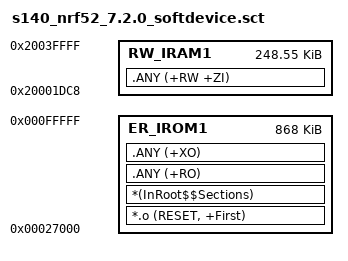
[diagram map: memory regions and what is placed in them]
; *************************************************************
; *** Scatter-Loading Description File generated by uVision ***
; *************************************************************

LR_IROM1 0x00027000 0x000D9000  {    ; load region size_region
  ER_IROM1 0x00027000 0x000D9000  {  ; load address = execution address
   *.o (RESET, +First)
   *(InRoot$$Sections)
   .ANY (+RO)
   .ANY (+XO)
  }
  RW_IRAM1 0x20001DC8 0x0003E238  {  ; RW data
   .ANY (+RW +ZI)
  }
}

